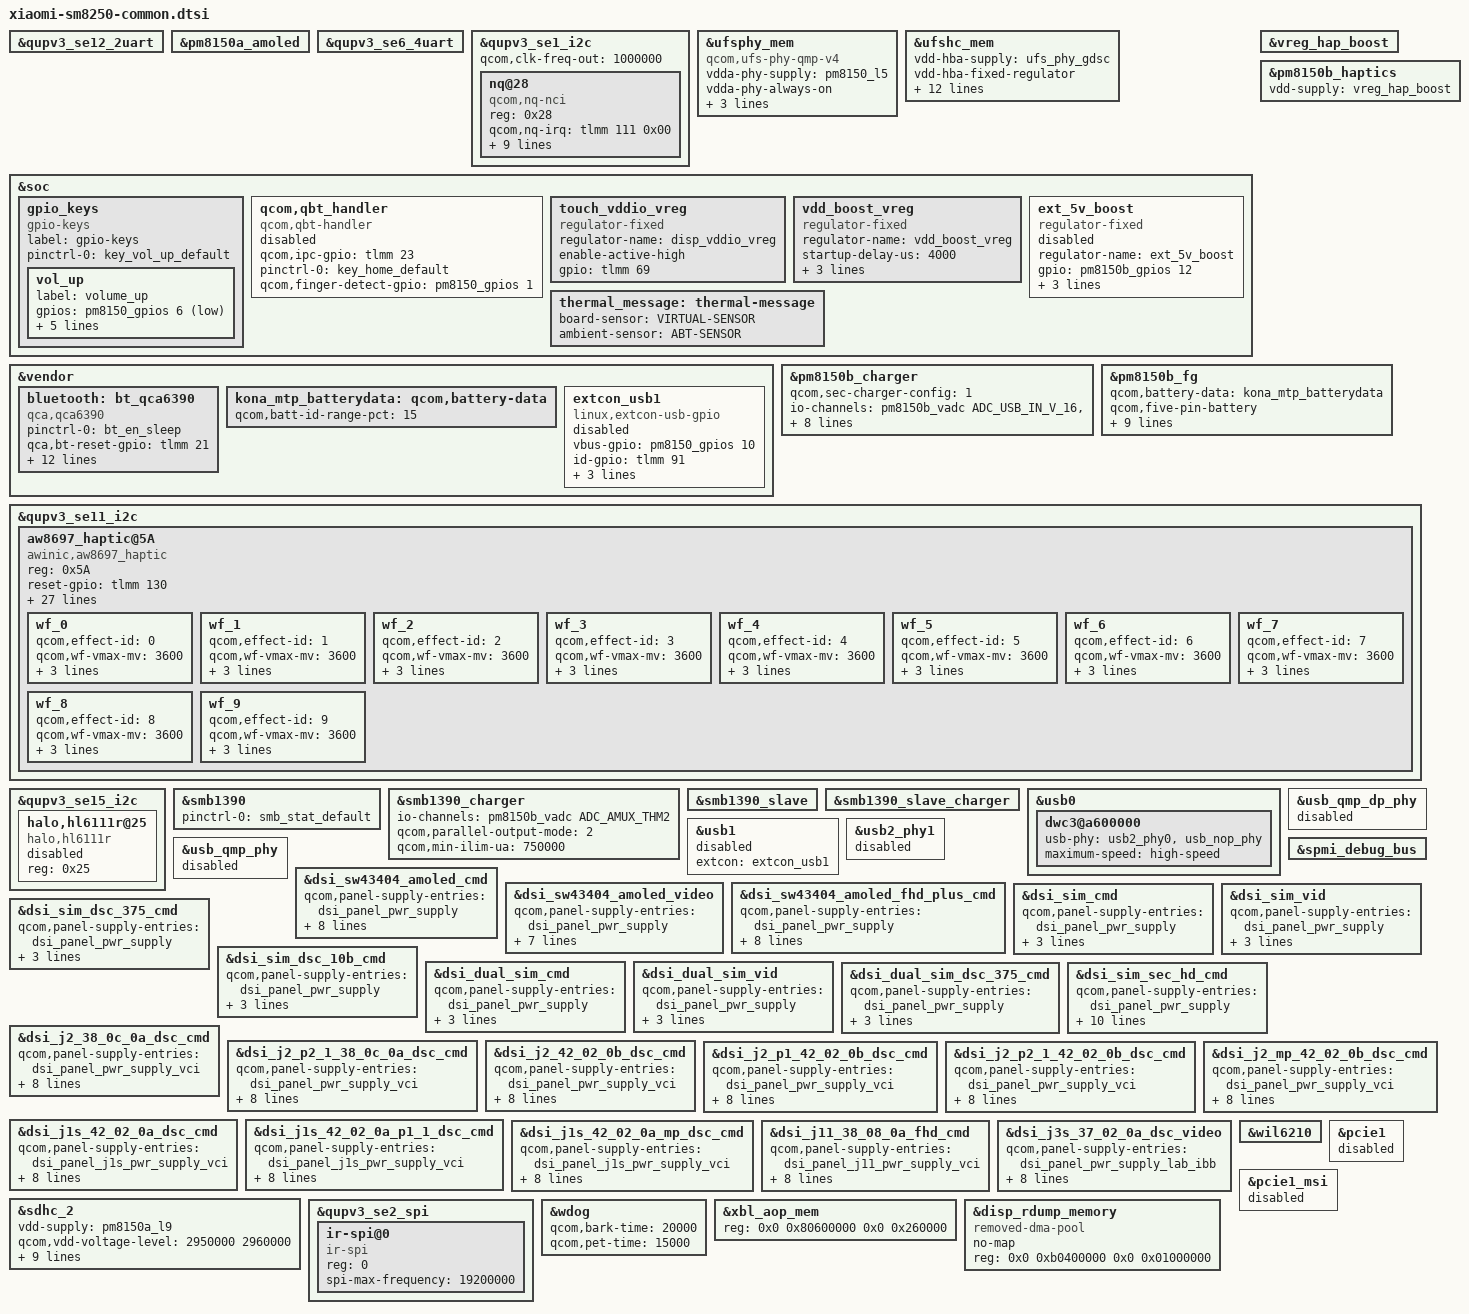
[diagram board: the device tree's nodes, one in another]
#include <dt-bindings/gpio/gpio.h>
#include <dt-bindings/input/input.h>

#include "kona-pmic-overlay.dtsi"
#include "kona-sde-display.dtsi"
#include "kona-thermal-overlay.dtsi"

&qupv3_se12_2uart {
	status = "ok";
};

&pm8150a_amoled {
	status = "ok";
};

&qupv3_se6_4uart {
	status = "ok";
};

&qupv3_se1_i2c {
	status = "ok";
	qcom,clk-freq-out = <1000000>;
	#address-cells = <1>;
	#size-cells = <0>;
	nq@28 {
		compatible = "qcom,nq-nci";
		reg = <0x28>;
		qcom,nq-irq = <&tlmm 111 0x00>;
		qcom,nq-ven = <&tlmm 83 0x00>;
		qcom,nq-firm = <&tlmm 110 0x00>;
		qcom,nq-clkreq = <&tlmm 7 0x00>;
		interrupt-parent = <&tlmm>;
		interrupts = <111 0>;
		interrupt-names = "nfc_irq";
		pinctrl-names = "nfc_active", "nfc_suspend";
		pinctrl-0 = <&nfc_int_active &nfc_enable_active
				&nfc_clk_req_active>;
		pinctrl-1 = <&nfc_int_suspend &nfc_enable_suspend
				&nfc_clk_req_suspend>;
	};
};

&ufsphy_mem {
	compatible = "qcom,ufs-phy-qmp-v4";

	vdda-phy-supply = <&pm8150_l5>;
	vdda-phy-always-on;
	vdda-pll-supply = <&pm8150_l9>;
	vdda-phy-max-microamp = <89900>;
	vdda-pll-max-microamp = <18800>;

	status = "ok";
};

&ufshc_mem {
	vdd-hba-supply = <&ufs_phy_gdsc>;
	vdd-hba-fixed-regulator;
	vcc-supply = <&pm8150_l17>;
	vcc-voltage-level = <2504000 2950000>;
	vcc-low-voltage-sup;
	vccq-supply = <&pm8150_l6>;
	vccq2-supply = <&pm8150_s4>;
	vcc-max-microamp = <800000>;
	vccq-max-microamp = <800000>;
	vccq2-max-microamp = <800000>;

	qcom,vddp-ref-clk-supply = <&pm8150_l6>;
	qcom,vddp-ref-clk-max-microamp = <100>;
        qcom,vccq-parent-supply = <&pm8150a_s8>;
        qcom,vccq-parent-max-microamp = <210000>;

	status = "ok";
};

&soc {
	gpio_keys {
		compatible = "gpio-keys";
		label = "gpio-keys";

		pinctrl-names = "default";
		pinctrl-0 = <&key_vol_up_default>;

		vol_up {
			label = "volume_up";
			gpios = <&pm8150_gpios 6 GPIO_ACTIVE_LOW>;
			linux,input-type = <1>;
			linux,code = <KEY_VOLUMEUP>;
			gpio-key,wakeup;
			debounce-interval = <15>;
			linux,can-disable;
		};
	};

	qcom,qbt_handler {
		compatible = "qcom,qbt-handler";
		qcom,ipc-gpio = <&tlmm 23 0>;
		pinctrl-names = "default";
		pinctrl-0 = <&key_home_default>;
		qcom,finger-detect-gpio = <&pm8150_gpios 1 0>;
		status = "disabled";
	};

	touch_vddio_vreg: touch_vddio_vreg {
		compatible = "regulator-fixed";
		regulator-name = "disp_vddio_vreg";
		/*startup-delay-us = <4000>;*/
		enable-active-high;
		/*regulator-boot-on*/
		gpio = <&tlmm 69 0>;
	 };

	vdd_boost_vreg: vdd_boost_vreg {
		compatible = "regulator-fixed";
		regulator-name = "vdd_boost_vreg";
		startup-delay-us = <4000>;
		enable-active-high;
		regulator-always-on;
		gpio = <&pm8150b_gpios 5 0>;
	 };

	 ext_5v_boost: ext_5v_boost {
		compatible = "regulator-fixed";
		status = "disabled";
		regulator-name = "ext_5v_boost";
		gpio = <&pm8150b_gpios 12 GPIO_ACTIVE_HIGH>;
		enable-active-high;
		regulator-enable-ramp-delay = <1600>;

		pinctrl-names = "default";
		pinctrl-0 = <&otg_vbus_boost_default>;
	};

	thermal_message: thermal-message {
		board-sensor = "VIRTUAL-SENSOR";
		ambient-sensor = "ABT-SENSOR";
	};
};

&vendor {
	bluetooth: bt_qca6390 {
		compatible = "qca,qca6390";
		pinctrl-names = "default";
		pinctrl-0 = <&bt_en_sleep>;
		qca,bt-reset-gpio = <&tlmm 21 0>; /* BT_EN */
                qca,bt-sw-ctrl-gpio = <&tlmm 124 0>; /* SW_CTRL */
		qca,bt-vdd-aon-supply = <&pm8150_s6>;
		qca,bt-vdd-dig-supply = <&pm8009_s2>;
		qca,bt-vdd-rfa1-supply = <&pm8150_s5>;
		qca,bt-vdd-rfa2-supply = <&pm8150a_s8>;
		qca,bt-vdd-asd-supply = <&pm8150_l16>;

		qca,bt-vdd-aon-voltage-level = <950000 950000>;
		qca,bt-vdd-dig-voltage-level = <950000 952000>;
		qca,bt-vdd-rfa1-voltage-level = <1900000 1900000>;
		qca,bt-vdd-rfa2-voltage-level = <1350000 1350000>;
		qca,bt-vdd-asd-voltage-level = <3024000 3304000>;

		qca,bt-vdd-asd-current-level = <10000>;
	};

	kona_mtp_batterydata: qcom,battery-data {
		qcom,batt-id-range-pct = <15>;
		#include "fg-gen4-batterydata-alium-3600mah.dtsi"
		#include "fg-gen4-batterydata-ascent-3450mah.dtsi"
	};

	extcon_usb1: extcon_usb1 {
		compatible = "linux,extcon-usb-gpio";
		vbus-gpio = <&pm8150_gpios 10 GPIO_ACTIVE_HIGH>;
		id-gpio = <&tlmm 91 GPIO_ACTIVE_HIGH>;
		vbus-out-gpio = <&pm8150_gpios 9 GPIO_ACTIVE_HIGH>;

		pinctrl-names = "default";
		pinctrl-0 = <&usb2_vbus_det_default
			     &usb2_id_det_default
			     &usb2_vbus_boost_default>;
		status = "disabled";
	};
};

&vreg_hap_boost {
	status = "ok";
};

&pm8150b_haptics {
	vdd-supply = <&vreg_hap_boost>;
};

&pm8150b_charger {
	status = "ok";
	qcom,sec-charger-config = <1>;
	//qcom,auto-recharge-soc = <98>;
	io-channels = <&pm8150b_vadc ADC_USB_IN_V_16>,
			<&pm8150b_vadc ADC_MID_CHG_DIV6>,
			<&pm8150b_vadc ADC_USB_IN_I>,
			<&pm8150b_vadc ADC_SBUx>,
			<&pm8150b_vadc ADC_VPH_PWR>,
			<&pm8150b_vadc ADC_CHG_TEMP>;
	io-channel-names = "usb_in_voltage",
			"mid_voltage",
			"usb_in_current",
			"sbux_res",
			"vph_voltage",
			"chg_temp";
	qcom,battery-data = <&kona_mtp_batterydata>;
	//qcom,step-charging-enable;
	//qcom,sw-jeita-enable;
	qcom,wd-bark-time-secs = <16>;
	//qcom,suspend-input-on-debug-batt;
	//qcom,fcc-stepping-enable;
        qcom,smb-internal-pull-kohm = <0>;
};

&pm8150b_fg {
	status = "ok";
	qcom,battery-data = <&kona_mtp_batterydata>;
	qcom,five-pin-battery;
	qcom,cl-wt-enable;
	qcom,soc-scale-mode-en;
        qcom,force-calib-level = <130>;
	/* ESR fast calibration */
	qcom,fg-esr-timer-chg-fast = <0 7>;
	qcom,fg-esr-timer-dischg-fast = <0 7>;
	qcom,fg-esr-timer-chg-slow = <0 96>;
	qcom,fg-esr-timer-dischg-slow = <0 96>;
	qcom,fg-esr-cal-soc-thresh = <26 230>;
	qcom,fg-esr-cal-temp-thresh = <10 40>;
};

&qupv3_se11_i2c {
	status = "ok";
	aw8697_haptic@5A {
		compatible = "awinic,aw8697_haptic";
		reg = <0x5A>;
		reset-gpio = <&tlmm 130 0>;
		irq-gpio = <&tlmm 129 0>;
		vib_mode = < 0 >;   /*mode:   RAM mode->0; CONT mode -> 1*/
		vib_f0_pre = < 1700 >;
		vib_f0_cali_percen = < 7 >;
		vib_cont_drv_lev = < 73 >;
		vib_cont_drv_lvl_ov = < 73 >;
		vib_cont_td = < 0xf06c >;
		vib_cont_zc_thr = < 0x08f8 >;  /*hq 0x08F8 */
		vib_cont_num_brk = < 3 >;
		vib_f0_coeff = < 260 >; /*Don't modify it    2.604167*/
		vib_f0_trace_parameter = < 9 3 1 31 >;
		vib_bemf_config = < 0 0x08 0x03 0xf8 >;
		vib_sw_brake = < 0x2c >;
		vib_tset = < 0x12 >;
		vib_r_spare = < 0x68 >;
		vib_bstdbg = < 0x30 0xeb 0xd4 0 0 0 >;
		vib_effect_id_boundary = < 10 >;
		vib_effect_max = < 170 >;
		vib_trig_config = < 0 1 0 1 2
						0 1 0 1 2
						0 1 0 1 2 >;
		vib_bst_vol_default = < 0x10 >;
		vib_bst_vol_ram = < 0x10 >;
		vib_bst_vol_rtp = < 0x10 >;
		vib_rtp_time = < 20 20 20 20 20 20 20 20 20000 15000
				 15000 20000 25000 15000 30000 25000 20000 20000 20000 20000
				 20000 20000 20000 20000 20000 20000 20000 20000 20000 20000
				 20000 20000 20000 20000 20000 20000 20000 20000 20000 20000
				 20000 20000 20000 20000 20000 20000 20000 20000 20000 20000
				 20000 20000 20000 20000 20000 20000 20000 20000 20000 20000
				 20000 20000 20000 20000 20000 20000 20000 20000 20000 20000
				 20000 20000 20000 20000 20000 20000 20000 20000 20000 20000
				 20000 20000 20000 20000 20000 20000 20000 20000 20000 20000
				 20000 20000 20000 20000 20000 20000 20000 20000 20000 20000
				 20000 20000 20000 20000 20000 20000 20000 20000 20000 20000
				 20000 20000 20000 20000 20000 20000 20000 20000 20000 20000
				 20000 20000 20000 20000 20000 20000 20000 20000 20000 20000
				 20000 20000 20000 20000 20000 20000 20000 20000 20000 20000
				 20000 20000 20000 20000 20000 20000 20000 20000 20000 20000
				 20000 20000 20000 20000 20000 20000 20000 20000 20000 20000
				 20000 20000 20000 20000 20000 20000 20000 20000 20000 20000
				 20000 20000 20000 20000 20000 >;
		pinctrl-names = "aw8697_reset_reset","aw8697_reset_active","aw8697_interrupt_active";
		pinctrl-0 = <&aw8697_gpio_reset>;
		pinctrl-1 = <&aw8697_gpio_reset_output_high>;
		pinctrl-2 = <&aw8697_gpio_int>;
		status = "ok";
		wf_0 {
			/*CLICK*/
			qcom,effect-id = <0>;
			qcom,wf-vmax-mv = <3600>;
			qcom,wf-pattern = [3e 3e];
			qcom,wf-brake-pattern = [02 01 00 00];
			qcom,wf-play-rate-us = <20000>;
		};
		wf_1 {
			/*DOUBLE CLICK*/
			qcom,effect-id = <1>;
			qcom,wf-vmax-mv = <3600>;
			qcom,wf-pattern = [7e 3e];
			qcom,wf-brake-pattern = [03 01 00 00];
			qcom,wf-play-rate-us = <20000>;
		};
		wf_2 {
			/*TICK*/
			qcom,effect-id = <2>;
			qcom,wf-vmax-mv = <3600>;
			qcom,wf-pattern = [7e 3e];
			qcom,wf-brake-pattern = [02 01 00 00];
			qcom,wf-play-rate-us = <20000>;
		};
		wf_3 {
			/*THUD*/
			qcom,effect-id = <3>;
			qcom,wf-vmax-mv = <3600>;
			qcom,wf-pattern = [3e 3e];
			qcom,wf-brake-pattern = [02 01 00 00];
			qcom,wf-play-rate-us = <20000>;
		};
		wf_4 {
			/*POP*/
			qcom,effect-id = <4>;
			qcom,wf-vmax-mv = <3600>;
			qcom,wf-pattern = [3e 3e];
			qcom,wf-brake-pattern = [02 01 00 00];
			qcom,wf-play-rate-us = <28000>;
		};
		wf_5 {
			/*HEAVY CLICK*/
			qcom,effect-id = <5>;
			qcom,wf-vmax-mv = <3600>;
			qcom,wf-pattern = [7e 7e 7e];
			qcom,wf-brake-pattern = [03 03 01 00];
			qcom,wf-play-rate-us = <20000>;
		};
		wf_6 {
			/*id 6*/
			qcom,effect-id = <6>;
			qcom,wf-vmax-mv = <3600>;
			qcom,wf-pattern = [3e 3e];
			qcom,wf-brake-pattern = [02 01 00 00];
			qcom,wf-play-rate-us = <20000>;
		};
		wf_7 {
			/*id 7*/
			qcom,effect-id = <7>;
			qcom,wf-vmax-mv = <3600>;
			qcom,wf-pattern = [3e 3e];
			qcom,wf-brake-pattern = [02 01 00 00];
			qcom,wf-play-rate-us = <20000>;
		};
		wf_8 {
			/*id 8*/
			qcom,effect-id = <8>;
			qcom,wf-vmax-mv = <3600>;
			qcom,wf-pattern = [3e 3e];
			qcom,wf-brake-pattern = [02 01 00 00];
			qcom,wf-play-rate-us = <20000>;
		};
		wf_9 {
			/*id 9*/
			qcom,effect-id = <9>;
			qcom,wf-vmax-mv = <3600>;
			qcom,wf-pattern = [3e 3e];
			qcom,wf-brake-pattern = [02 01 00 00];
			qcom,wf-play-rate-us = <20000>;
		};
	};
};

&qupv3_se15_i2c {
	#address-cells = <1>;
	#size-cells = <0>;
#include "smb1390.dtsi"

	halo,hl6111r@25 {
		compatible = "halo,hl6111r";
		reg = <0x25>;
		status = "disabled";
	};
};

&smb1390 {
	pinctrl-names = "default";
	pinctrl-0 = <&smb_stat_default>;
	status = "ok";
};

&smb1390_charger {
	io-channels = <&pm8150b_vadc ADC_AMUX_THM2>;
	io-channel-names = "cp_die_temp";
	qcom,parallel-output-mode = <2>;
	qcom,min-ilim-ua = <750000>;
	status = "ok";
};

&smb1390_slave {
	status = "ok";
};

&smb1390_slave_charger {
	status = "ok";
};

&usb0 {
        dwc3@a600000 {
                usb-phy = <&usb2_phy0>, <&usb_nop_phy>;
                maximum-speed = "high-speed";
        };
};

&usb_qmp_dp_phy {
        status = "disabled";
};

&usb1 {
        extcon = <&extcon_usb1>;
        status = "disabled";
};

&usb2_phy1 {
        status = "disabled";
};

&usb_qmp_phy {
        status = "disabled";
};

&spmi_debug_bus {
	status = "ok";
};

&dsi_sw43404_amoled_cmd {
	qcom,panel-supply-entries = <&dsi_panel_pwr_supply>;
	qcom,mdss-dsi-bl-pmic-control-type = "bl_ctrl_dcs";
	qcom,mdss-dsi-bl-min-level = <1>;
	qcom,mdss-dsi-bl-max-level = <1023>;
	qcom,mdss-brightness-max-level = <255>;
	qcom,platform-te-gpio = <&tlmm 66 0>;
	qcom,platform-reset-gpio = <&tlmm 75 0>;
	qcom,mdss-dsi-panel-test-pin = <&tlmm 46 0>;
};

&dsi_sw43404_amoled_video {
	qcom,panel-supply-entries = <&dsi_panel_pwr_supply>;
	qcom,mdss-dsi-bl-pmic-control-type = "bl_ctrl_dcs";
	qcom,mdss-dsi-bl-min-level = <1>;
	qcom,mdss-dsi-bl-max-level = <1023>;
	qcom,mdss-brightness-max-level = <255>;
	qcom,platform-reset-gpio = <&tlmm 75 0>;
	qcom,mdss-dsi-panel-test-pin = <&tlmm 46 0>;
};

&dsi_sw43404_amoled_fhd_plus_cmd {
	qcom,panel-supply-entries = <&dsi_panel_pwr_supply>;
	qcom,mdss-dsi-bl-pmic-control-type = "bl_ctrl_dcs";
	qcom,mdss-dsi-bl-min-level = <1>;
	qcom,mdss-dsi-bl-max-level = <1023>;
	qcom,mdss-brightness-max-level = <255>;
	qcom,platform-te-gpio = <&tlmm 66 0>;
	qcom,platform-reset-gpio = <&tlmm 75 0>;
	qcom,mdss-dsi-panel-test-pin = <&tlmm 46 0>;
};

&dsi_sim_cmd {
	qcom,panel-supply-entries = <&dsi_panel_pwr_supply>;
	qcom,mdss-dsi-bl-pmic-control-type = "bl_ctrl_dcs";
	qcom,platform-reset-gpio = <&tlmm 75 0>;
};

&dsi_sim_vid {
	qcom,panel-supply-entries = <&dsi_panel_pwr_supply>;
	qcom,mdss-dsi-bl-pmic-control-type = "bl_ctrl_dcs";
	qcom,platform-reset-gpio = <&tlmm 75 0>;
};

&dsi_sim_dsc_375_cmd {
	qcom,panel-supply-entries = <&dsi_panel_pwr_supply>;
	qcom,mdss-dsi-bl-pmic-control-type = "bl_ctrl_dcs";
	qcom,platform-reset-gpio = <&tlmm 75 0>;
};

&dsi_sim_dsc_10b_cmd {
	qcom,panel-supply-entries = <&dsi_panel_pwr_supply>;
	qcom,mdss-dsi-bl-pmic-control-type = "bl_ctrl_dcs";
	qcom,platform-reset-gpio = <&tlmm 75 0>;
};

&dsi_dual_sim_cmd {
	qcom,panel-supply-entries = <&dsi_panel_pwr_supply>;
	qcom,mdss-dsi-bl-pmic-control-type = "bl_ctrl_dcs";
	qcom,platform-reset-gpio = <&tlmm 75 0>;
};

&dsi_dual_sim_vid {
	qcom,panel-supply-entries = <&dsi_panel_pwr_supply>;
	qcom,mdss-dsi-bl-pmic-control-type = "bl_ctrl_dcs";
	qcom,platform-reset-gpio = <&tlmm 75 0>;
};

&dsi_dual_sim_dsc_375_cmd {
	qcom,panel-supply-entries = <&dsi_panel_pwr_supply>;
	qcom,mdss-dsi-bl-pmic-control-type = "bl_ctrl_dcs";
	qcom,platform-reset-gpio = <&tlmm 75 0>;
};

&dsi_sim_sec_hd_cmd {
	qcom,panel-supply-entries = <&dsi_panel_pwr_supply>;
	qcom,panel-sec-supply-entries = <&dsi_panel_pwr_supply>;
	qcom,mdss-dsi-bl-pmic-control-type = "bl_ctrl_dcs";
	qcom,mdss-dsi-sec-bl-pmic-control-type = "bl_ctrl_dcs";
	qcom,mdss-dsi-bl-min-level = <1>;
	qcom,mdss-dsi-bl-max-level = <1023>;
	qcom,platform-reset-gpio = <&tlmm 75 0>;
	qcom,platform-sec-reset-gpio = <&tlmm 128 0>;
};

&dsi_j2_38_0c_0a_dsc_cmd {
	qcom,panel-supply-entries = <&dsi_panel_pwr_supply_vci>;
	qcom,mdss-dsi-bl-pmic-control-type = "bl_ctrl_dcs";
	qcom,mdss-dsi-bl-min-level = <2>;
	qcom,mdss-dsi-bl-max-level = <2047>;
	qcom,mdss-brightness-max-level = <2047>;
	qcom,mdss-brightness-init-level = <536>;
	qcom,platform-te-gpio = <&tlmm 66 0>;
	qcom,platform-reset-gpio = <&tlmm 12 0>;
};

&dsi_j2_p2_1_38_0c_0a_dsc_cmd {
	qcom,panel-supply-entries = <&dsi_panel_pwr_supply_vci>;
	qcom,mdss-dsi-bl-pmic-control-type = "bl_ctrl_dcs";
	qcom,mdss-dsi-bl-min-level = <2>;
	qcom,mdss-dsi-bl-max-level = <2047>;
	qcom,mdss-brightness-max-level = <2047>;
	qcom,mdss-brightness-init-level = <536>;
	qcom,platform-te-gpio = <&tlmm 66 0>;
	qcom,platform-reset-gpio = <&tlmm 12 0>;
};

&dsi_j2_42_02_0b_dsc_cmd {
	qcom,panel-supply-entries = <&dsi_panel_pwr_supply_vci>;
	qcom,mdss-dsi-bl-pmic-control-type = "bl_ctrl_dcs";
	qcom,mdss-dsi-bl-min-level = <1>;
	qcom,mdss-dsi-bl-max-level = <2047>;
	qcom,mdss-brightness-max-level = <2047>;
	qcom,mdss-brightness-init-level = <536>;
	qcom,platform-te-gpio = <&tlmm 66 0>;
	qcom,platform-reset-gpio = <&tlmm 12 0>;
};

&dsi_j2_p1_42_02_0b_dsc_cmd {
	qcom,panel-supply-entries = <&dsi_panel_pwr_supply_vci>;
	qcom,mdss-dsi-bl-pmic-control-type = "bl_ctrl_dcs";
	qcom,mdss-dsi-bl-min-level = <1>;
	qcom,mdss-dsi-bl-max-level = <2047>;
	qcom,mdss-brightness-max-level = <2047>;
	qcom,mdss-brightness-init-level = <536>;
	qcom,platform-te-gpio = <&tlmm 66 0>;
	qcom,platform-reset-gpio = <&tlmm 12 0>;
};

&dsi_j2_p2_1_42_02_0b_dsc_cmd {
	qcom,panel-supply-entries = <&dsi_panel_pwr_supply_vci>;
	qcom,mdss-dsi-bl-pmic-control-type = "bl_ctrl_dcs";
	qcom,mdss-dsi-bl-min-level = <1>;
	qcom,mdss-dsi-bl-max-level = <2047>;
	qcom,mdss-brightness-max-level = <2047>;
	qcom,mdss-brightness-init-level = <536>;
	qcom,platform-te-gpio = <&tlmm 66 0>;
	qcom,platform-reset-gpio = <&tlmm 12 0>;
};

&dsi_j2_mp_42_02_0b_dsc_cmd {
	qcom,panel-supply-entries = <&dsi_panel_pwr_supply_vci>;
	qcom,mdss-dsi-bl-pmic-control-type = "bl_ctrl_dcs";
	qcom,mdss-dsi-bl-min-level = <1>;
	qcom,mdss-dsi-bl-max-level = <2047>;
	qcom,mdss-brightness-max-level = <2047>;
	qcom,mdss-brightness-init-level = <536>;
	qcom,platform-te-gpio = <&tlmm 66 0>;
	qcom,platform-reset-gpio = <&tlmm 12 0>;
};

&dsi_j1s_42_02_0a_dsc_cmd {
        qcom,panel-supply-entries = <&dsi_panel_j1s_pwr_supply_vci>;
        qcom,mdss-dsi-bl-pmic-control-type = "bl_ctrl_dcs";
        qcom,mdss-dsi-bl-min-level = <1>;
        qcom,mdss-dsi-bl-max-level = <4095>;
        qcom,mdss-brightness-max-level = <4095>;
        qcom,mdss-brightness-init-level = <536>;
        qcom,platform-te-gpio = <&tlmm 66 0>;
        qcom,platform-reset-gpio = <&tlmm 12 0>;
};

&dsi_j1s_42_02_0a_p1_1_dsc_cmd {
        qcom,panel-supply-entries = <&dsi_panel_j1s_pwr_supply_vci>;
        qcom,mdss-dsi-bl-pmic-control-type = "bl_ctrl_dcs";
        qcom,mdss-dsi-bl-min-level = <1>;
        qcom,mdss-dsi-bl-max-level = <4095>;
        qcom,mdss-brightness-max-level = <4095>;
        qcom,mdss-brightness-init-level = <536>;
        qcom,platform-te-gpio = <&tlmm 66 0>;
        qcom,platform-reset-gpio = <&tlmm 12 0>;
};

&dsi_j1s_42_02_0a_mp_dsc_cmd {
        qcom,panel-supply-entries = <&dsi_panel_j1s_pwr_supply_vci>;
        qcom,mdss-dsi-bl-pmic-control-type = "bl_ctrl_dcs";
        qcom,mdss-dsi-bl-min-level = <1>;
        qcom,mdss-dsi-bl-max-level = <4095>;
        qcom,mdss-brightness-max-level = <4095>;
        qcom,mdss-brightness-init-level = <536>;
        qcom,platform-te-gpio = <&tlmm 66 0>;
        qcom,platform-reset-gpio = <&tlmm 12 0>;
};

&dsi_j11_38_08_0a_fhd_cmd {
	qcom,panel-supply-entries = <&dsi_panel_j11_pwr_supply_vci>;
	qcom,mdss-dsi-bl-pmic-control-type = "bl_ctrl_dcs";
	qcom,mdss-dsi-bl-min-level = <2>;
	qcom,mdss-dsi-bl-max-level = <2047>;
	qcom,mdss-brightness-max-level = <2047>;
	qcom,mdss-brightness-init-level = <536>;
	/*
	qcom,mdss-dsi-mode-sel-gpio-state = "single_port";
	qcom,panel-mode-gpio = <&tlmm 7 0>;
	*/
	qcom,platform-te-gpio = <&tlmm 66 0>;
	qcom,platform-reset-gpio = <&tlmm 46 0>;
};

&dsi_j3s_37_02_0a_dsc_video {
	qcom,panel-supply-entries = <&dsi_panel_pwr_supply_lab_ibb>;
	qcom,mdss-dsi-bl-pmic-control-type = "bl_ctrl_wled";
	qcom,mdss-dsi-bl-min-level = <2>;
	qcom,mdss-dsi-bl-max-level = <4095>;
	qcom,mdss-brightness-max-level = <4095>;
	qcom,mdss-brightness-init-level = <410>;
	qcom,platform-te-gpio = <&tlmm 66 0>;
	qcom,platform-reset-gpio = <&tlmm 12 0>;
};

&sdhc_2 {
	vdd-supply = <&pm8150a_l9>;
	qcom,vdd-voltage-level = <2950000 2960000>;
	qcom,vdd-current-level = <200 800000>;

	vdd-io-supply = <&pm8150a_l6>;
	qcom,vdd-io-voltage-level = <1808000 2960000>;
	qcom,vdd-io-current-level = <200 22000>;

	pinctrl-names = "active", "sleep";
        pinctrl-0 = <&sdc2_clk_on  &sdc2_cmd_on &sdc2_data_on &storage_cd>;
        pinctrl-1 = <&sdc2_clk_off &sdc2_cmd_off &sdc2_data_off &storage_cd>;

        cd-gpios = <&tlmm 77 GPIO_ACTIVE_LOW>;

	status = "ok";
};

&usb1 {
	extcon = <&extcon_usb1>;
};

&wil6210 {
	status = "ok";
};

&pcie1 {
	status = "disabled";
};

&pcie1_msi {
	status = "disabled";
};

&qupv3_se2_spi {
	status = "ok";
	ir-spi@0 {
		compatible = "ir-spi";
		reg = <0>;
		spi-max-frequency = <19200000>;
		status = "ok";
	};
};

&wdog {
	qcom,bark-time = <20000>;
	qcom,pet-time = <15000>;
};

&xbl_aop_mem {
	reg = <0x0 0x80600000 0x0 0x260000>;
};

&disp_rdump_memory {
	compatible = "removed-dma-pool";
	no-map;
	reg = <0x0 0xb0400000 0x0 0x01000000>;
};
